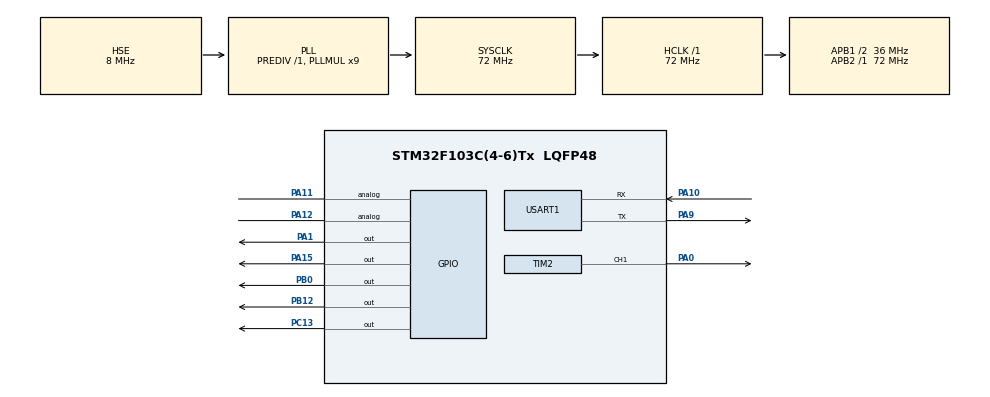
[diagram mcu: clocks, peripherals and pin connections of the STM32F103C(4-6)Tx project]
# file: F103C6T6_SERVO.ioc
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Mcu.Family=STM32F1
Mcu.Name=STM32F103C(4-6)Tx
Mcu.Package=LQFP48
NVIC.PriorityGroup=NVIC_PRIORITYGROUP_4
NVIC.TIM2_IRQn=true\:0\:0\:false\:false\:true\:true\:true\:true
PA0-WKUP.Signal=S_TIM2_CH1_ETR
PA1.Signal=GPIO_Output
PA10.Mode=Asynchronous
PA10.Signal=USART1_RX
PA11.Signal=GPIO_Analog
PA12.Signal=GPIO_Analog
PA13.Mode=Serial_Wire
PA13.Signal=SYS_JTMS-SWDIO
PA14.Mode=Serial_Wire
PA14.Signal=SYS_JTCK-SWCLK
PA15.Signal=GPIO_Output
PA9.Mode=Asynchronous
PA9.Signal=USART1_TX
PB0.Signal=GPIO_Output
PB12.Signal=GPIO_Output
PC13-TAMPER-RTC.Signal=GPIO_Output
PD0-OSC_IN.Mode=HSE-External-Oscillator
PD0-OSC_IN.Signal=RCC_OSC_IN
PD1-OSC_OUT.Mode=HSE-External-Oscillator
PD1-OSC_OUT.Signal=RCC_OSC_OUT
ProjectManager.HeapSize=0x200
ProjectManager.StackSize=0x400
ProjectManager.TargetToolchain=STM32CubeIDE
RCC.AHBFreq_Value=72000000
RCC.APB1CLKDivider=RCC_HCLK_DIV2
RCC.APB1Freq_Value=36000000
RCC.APB1TimFreq_Value=72000000
RCC.APB2Freq_Value=72000000
RCC.APB2TimFreq_Value=72000000
RCC.HCLKFreq_Value=72000000
RCC.PLLMUL=RCC_PLL_MUL9
RCC.PLLSourceVirtual=RCC_PLLSOURCE_HSE
RCC.SYSCLKFreq_VALUE=72000000
RCC.SYSCLKSource=RCC_SYSCLKSOURCE_PLLCLK
RCC.USBFreq_Value=72000000
SH.S_TIM2_CH1_ETR.0=TIM2_CH1,PWM Generation1 CH1
TIM2.Channel-PWM\ Generation1\ CH1=TIM_CHANNEL_1
TIM2.Period=1000-1
TIM2.Prescaler=1440-1
USART1.VirtualMode=VM_ASYNC
VP_TIM2_VS_ClockSourceINT.Mode=Internal
board=custom

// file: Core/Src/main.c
/* USER CODE BEGIN Header */
/**
  ******************************************************************************
  * @file           : main.c
  * @brief          : Main program body
  ******************************************************************************
  * @attention
  *
  * Copyright (c) 2023 STMicroelectronics.
  * All rights reserved.
  *
  * This software is licensed under terms that can be found in the LICENSE file
  * in the root directory of this software component.
  * If no LICENSE file comes with this software, it is provided AS-IS.
  *
  ******************************************************************************
  */
/* USER CODE END Header */
#include "main.h"

TIM_HandleTypeDef htim2;

UART_HandleTypeDef huart1;

void SystemClock_Config(void);
static void MX_GPIO_Init(void);
static void MX_TIM2_Init(void);
static void MX_USART1_UART_Init(void);

int main(void)
{

  /* MCU Configuration--------------------------------------------------------*/

  /* Reset of all peripherals, Initializes the Flash interface and the Systick. */
  HAL_Init();

  /* USER CODE BEGIN Init */

// #ifdef __GNUC__
  /* With GCC/RAISONANCE, small printf (option LD Linker->Libraries->Small printf
     set to 'Yes') calls __io_putchar() */
  //#define PUTCHAR_PROTOTYPE int __io_putchar(int ch)
//#else
  //#define PUTCHAR_PROTOTYPE int fputc(int ch, FILE *f)
//#endif /* __GNUC__ */
/**
  * @brief  Retargets the C library printf function to the USART.
  * @param  None
  * @retval None
  */
//PUTCHAR_PROTOTYPE
//{
  /* Place your implementation of fputc here */
  /* e.g. write a character to the EVAL_COM1 and Loop until the end of transmission */
 // HAL_UART_Transmit(&huart1, (uint8_t *)&ch, 1, 0xFFFF);

 // return ch

  /* USER CODE END Init */

  /* Configure the system clock */
  SystemClock_Config();

  /* Initialize all configured peripherals */
  MX_GPIO_Init();
  MX_TIM2_Init();
  MX_USART1_UART_Init();
  /* USER CODE BEGIN 2 */
  HAL_TIM_PWM_Start(&htim2, TIM_CHANNEL_1);    // to enable the PWM channel output signal.
  // hardware Timer2, PWM_CH1 = Port A0 PWM out
  /* USER CODE END 2 */
  uint8_t data2[] = "STM32F103C6T6 / Port A0 PWM output and USART1!";
  HAL_UART_Transmit(&huart1, data2, sizeof(data2), HAL_MAX_DELAY);
  /* Infinite loop */
  while (1)
  {

    /* USER CODE BEGIN 3 */
	  // To change the duty cycle of the PWM signal,
	  // need to write the value to the corresponding CCR register.
	  htim2.Instance->CCR1 = 25;  // 25 duty cycle is .5 ms
	  HAL_Delay(1000);			// DutyCycle = CCR/ARR = .5 = 25 / 50
	  htim2.Instance->CCR1 = 75;  // 75 duty cycle is 1.5 ms
	  HAL_Delay(1000);			// DutyCycle = CCR/ARR = 1.5 = 75 / 50
	  htim2.Instance->CCR1 = 125;  // 125 duty cycle is 2.5 ms
	  HAL_Delay(1000);			// DutyCycle = CCR/ARR = 2.5 = 125 / 50

	  HAL_GPIO_TogglePin (GPIOA, GPIO_PIN_1);	  HAL_Delay (50);
	  HAL_GPIO_TogglePin (GPIOB, GPIO_PIN_0);	  HAL_Delay (50);
	  HAL_GPIO_TogglePin (GPIOC, GPIO_PIN_13);	  HAL_Delay (50);
	  uint8_t data[] = "Toggle C13 / Serial Baud 2400, USART1!";
	  HAL_UART_Transmit(&huart1, data, sizeof(data), HAL_MAX_DELAY);

  }
  /* USER CODE END 3 */
}

void SystemClock_Config(void)
{
  RCC_OscInitTypeDef RCC_OscInitStruct = {0};
  RCC_ClkInitTypeDef RCC_ClkInitStruct = {0};

  /** Initializes the RCC Oscillators according to the specified parameters
  * in the RCC_OscInitTypeDef structure.
  */
  RCC_OscInitStruct.OscillatorType = RCC_OSCILLATORTYPE_HSE;
  RCC_OscInitStruct.HSEState = RCC_HSE_ON;
  RCC_OscInitStruct.HSEPredivValue = RCC_HSE_PREDIV_DIV1;
  RCC_OscInitStruct.HSIState = RCC_HSI_ON;
  RCC_OscInitStruct.PLL.PLLState = RCC_PLL_ON;
  RCC_OscInitStruct.PLL.PLLSource = RCC_PLLSOURCE_HSE;
  RCC_OscInitStruct.PLL.PLLMUL = RCC_PLL_MUL9;
  if (HAL_RCC_OscConfig(&RCC_OscInitStruct) != HAL_OK)
  {
    Error_Handler();
  }

  /** Initializes the CPU, AHB and APB buses clocks
  */
  RCC_ClkInitStruct.ClockType = RCC_CLOCKTYPE_HCLK|RCC_CLOCKTYPE_SYSCLK
                              |RCC_CLOCKTYPE_PCLK1|RCC_CLOCKTYPE_PCLK2;
  RCC_ClkInitStruct.SYSCLKSource = RCC_SYSCLKSOURCE_PLLCLK;
  RCC_ClkInitStruct.AHBCLKDivider = RCC_SYSCLK_DIV1;
  RCC_ClkInitStruct.APB1CLKDivider = RCC_HCLK_DIV2;
  RCC_ClkInitStruct.APB2CLKDivider = RCC_HCLK_DIV1;

  if (HAL_RCC_ClockConfig(&RCC_ClkInitStruct, FLASH_LATENCY_2) != HAL_OK)
  {
    Error_Handler();
  }
}

static void MX_TIM2_Init(void)
{

  TIM_ClockConfigTypeDef sClockSourceConfig = {0};
  TIM_MasterConfigTypeDef sMasterConfig = {0};
  TIM_OC_InitTypeDef sConfigOC = {0};

  htim2.Instance = TIM2;
  htim2.Init.Prescaler = 1440-1;
  htim2.Init.CounterMode = TIM_COUNTERMODE_UP;
  htim2.Init.Period = 1000-1;
  htim2.Init.ClockDivision = TIM_CLOCKDIVISION_DIV1;
  htim2.Init.AutoReloadPreload = TIM_AUTORELOAD_PRELOAD_DISABLE;
  if (HAL_TIM_Base_Init(&htim2) != HAL_OK)
  {
    Error_Handler();
  }
  sClockSourceConfig.ClockSource = TIM_CLOCKSOURCE_INTERNAL;
  if (HAL_TIM_ConfigClockSource(&htim2, &sClockSourceConfig) != HAL_OK)
  {
    Error_Handler();
  }
  if (HAL_TIM_PWM_Init(&htim2) != HAL_OK)
  {
    Error_Handler();
  }
  sMasterConfig.MasterOutputTrigger = TIM_TRGO_RESET;
  sMasterConfig.MasterSlaveMode = TIM_MASTERSLAVEMODE_DISABLE;
  if (HAL_TIMEx_MasterConfigSynchronization(&htim2, &sMasterConfig) != HAL_OK)
  {
    Error_Handler();
  }
  sConfigOC.OCMode = TIM_OCMODE_PWM1;
  sConfigOC.Pulse = 0;
  sConfigOC.OCPolarity = TIM_OCPOLARITY_HIGH;
  sConfigOC.OCFastMode = TIM_OCFAST_DISABLE;
  if (HAL_TIM_PWM_ConfigChannel(&htim2, &sConfigOC, TIM_CHANNEL_1) != HAL_OK)
  {
    Error_Handler();
  }
  HAL_TIM_MspPostInit(&htim2);

}

static void MX_USART1_UART_Init(void)
{

  huart1.Instance = USART1;
  huart1.Init.BaudRate = 2400;
  huart1.Init.WordLength = UART_WORDLENGTH_8B;
  huart1.Init.StopBits = UART_STOPBITS_1;
  huart1.Init.Parity = UART_PARITY_NONE;
  huart1.Init.Mode = UART_MODE_TX_RX;
  huart1.Init.HwFlowCtl = UART_HWCONTROL_NONE;
  huart1.Init.OverSampling = UART_OVERSAMPLING_16;
  if (HAL_UART_Init(&huart1) != HAL_OK)
  {
    Error_Handler();
  }

}

static void MX_GPIO_Init(void)
{
  GPIO_InitTypeDef GPIO_InitStruct = {0};

  /* GPIO Ports Clock Enable */
  __HAL_RCC_GPIOC_CLK_ENABLE();
  __HAL_RCC_GPIOD_CLK_ENABLE();
  __HAL_RCC_GPIOA_CLK_ENABLE();
  __HAL_RCC_GPIOB_CLK_ENABLE();

  /*Configure GPIO pin Output Level */
  HAL_GPIO_WritePin(GPIOC, GPIO_PIN_13, GPIO_PIN_RESET);

  /*Configure GPIO pin Output Level */
  HAL_GPIO_WritePin(GPIOA, GPIO_PIN_1|GPIO_PIN_15, GPIO_PIN_RESET);

  /*Configure GPIO pin Output Level */
  HAL_GPIO_WritePin(GPIOB, GPIO_PIN_0|GPIO_PIN_12, GPIO_PIN_RESET);

  /*Configure GPIO pin : PC13 */
  GPIO_InitStruct.Pin = GPIO_PIN_13;
  GPIO_InitStruct.Mode = GPIO_MODE_OUTPUT_PP;
  GPIO_InitStruct.Pull = GPIO_NOPULL;
  GPIO_InitStruct.Speed = GPIO_SPEED_FREQ_LOW;
  HAL_GPIO_Init(GPIOC, &GPIO_InitStruct);

  /*Configure GPIO pins : PA1 PA15 */
  GPIO_InitStruct.Pin = GPIO_PIN_1|GPIO_PIN_15;
  GPIO_InitStruct.Mode = GPIO_MODE_OUTPUT_PP;
  GPIO_InitStruct.Pull = GPIO_NOPULL;
  GPIO_InitStruct.Speed = GPIO_SPEED_FREQ_LOW;
  HAL_GPIO_Init(GPIOA, &GPIO_InitStruct);

  /*Configure GPIO pins : PB0 PB12 */
  GPIO_InitStruct.Pin = GPIO_PIN_0|GPIO_PIN_12;
  GPIO_InitStruct.Mode = GPIO_MODE_OUTPUT_PP;
  GPIO_InitStruct.Pull = GPIO_NOPULL;
  GPIO_InitStruct.Speed = GPIO_SPEED_FREQ_LOW;
  HAL_GPIO_Init(GPIOB, &GPIO_InitStruct);

  /*Configure GPIO pins : PA11 PA12 */
  GPIO_InitStruct.Pin = GPIO_PIN_11|GPIO_PIN_12;
  GPIO_InitStruct.Mode = GPIO_MODE_ANALOG;
  HAL_GPIO_Init(GPIOA, &GPIO_InitStruct);

}

void Error_Handler(void)
{
  __disable_irq();
  while (1)
  {
  }
}
